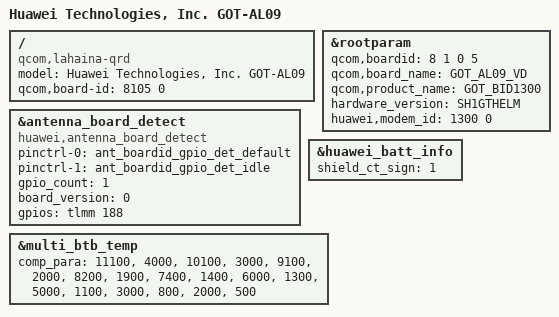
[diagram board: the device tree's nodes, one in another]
/dts-v1/;
/plugin/;

#include "../common/common.dtsi"
#include "huawei_wifi.dtsi"
#include "huawei-bt.dtsi"
/ {
    /* bsp_replace_info @ model = "Huawei Technologies, Inc. %product_name%"; */
    model = "Huawei Technologies, Inc. GOT-AL09";
    compatible = "qcom,lahaina-qrd", "qcom,lahaina", "qcom,qrd";
    /* bsp_replace_info @ qcom,board-id = <%boardid% 0>; */
    qcom,board-id = <8105 0>;
};

&rootparam {
    /* bsp_replace_info @ qcom,boardid = <%boardid_split%>; */
    /* auto_key_info @ name: boardid type: uint32 default: 0 */
    qcom,boardid = <8 1 0 5>;
    /* bsp_replace_info @ qcom,board_name = "%board_name%"; */
    qcom,board_name = "GOT_AL09_VD";
    /* bsp_replace_info @ qcom,product_name = "%product_name%"; */
    qcom,product_name = "GOT_BID1300";
    /* bsp_replace_info @ hardware_version = "%hardware_version%"; */
    hardware_version = "SH1GTHELM";
    /* bsp_replace_info @ huawei,modem_id = <%modem_id% 0x0>; */
    huawei,modem_id = <1300 0>;
};

&antenna_board_detect {
	compatible = "huawei,antenna_board_detect";
	pinctrl-names = "default", "idle";
	pinctrl-0 = <&ant_boardid_gpio_det_default>;
	pinctrl-1 = <&ant_boardid_gpio_det_idle>;
	gpio_count = <1>;
	board_version = <0>;
	gpios = <&tlmm 188 0>;
	status = "okay";
};

&huawei_batt_info {
	shield_ct_sign = <1>;
};

&multi_btb_temp {
	comp_para =
		"11100", "4000",
		"10100", "3000",
		"9100", "2000",
		"8200", "1900",
		"7400", "1400",
		"6000", "1300",
		"5000", "1100",
		"3000", "800",
		"2000", "500";
};
